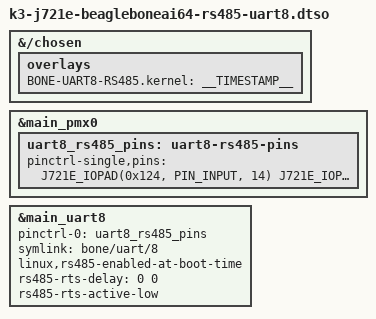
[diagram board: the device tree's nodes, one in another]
// SPDX-License-Identifier: GPL-2.0-only OR MIT
/*
 * Copyright (C) 2026 Pranav Raja
 * DT Overlay for RS485 support on UART8
 * P8.28 - UART8_RXD
 * P8.29 - UART8_TXD
 * P8.20 - UART8_RTSn
 */

/dts-v1/;
/plugin/;

#include <dt-bindings/gpio/gpio.h>
#include "k3-pinctrl.h"

&{/chosen} {
    overlays {
        BONE-UART8-RS485.kernel = __TIMESTAMP__;
    };
};

&main_pmx0 {
    uart8_rs485_pins: uart8-rs485-pins {
        pinctrl-single,pins = <
            J721E_IOPAD(0x124, PIN_INPUT, 14)  /* P8_28 (Y24) UART8_RXD */
            J721E_IOPAD(0x128, PIN_OUTPUT, 14) /* P8_29 (AA25) UART8_TXD */
            J721E_IOPAD(0x134, PIN_OUTPUT, 14) /* P8_20 (AF26) UART8_RTSn */
        >;
    };
};

&main_uart8 {
    pinctrl-names = "default";
    pinctrl-0 = <&uart8_rs485_pins>;
    symlink = "bone/uart/8";
    status = "okay";

    linux,rs485-enabled-at-boot-time;
    rs485-rts-delay = <0 0>;

    /* Use this line based on your hardware */
    rs485-rts-active-low;
};
